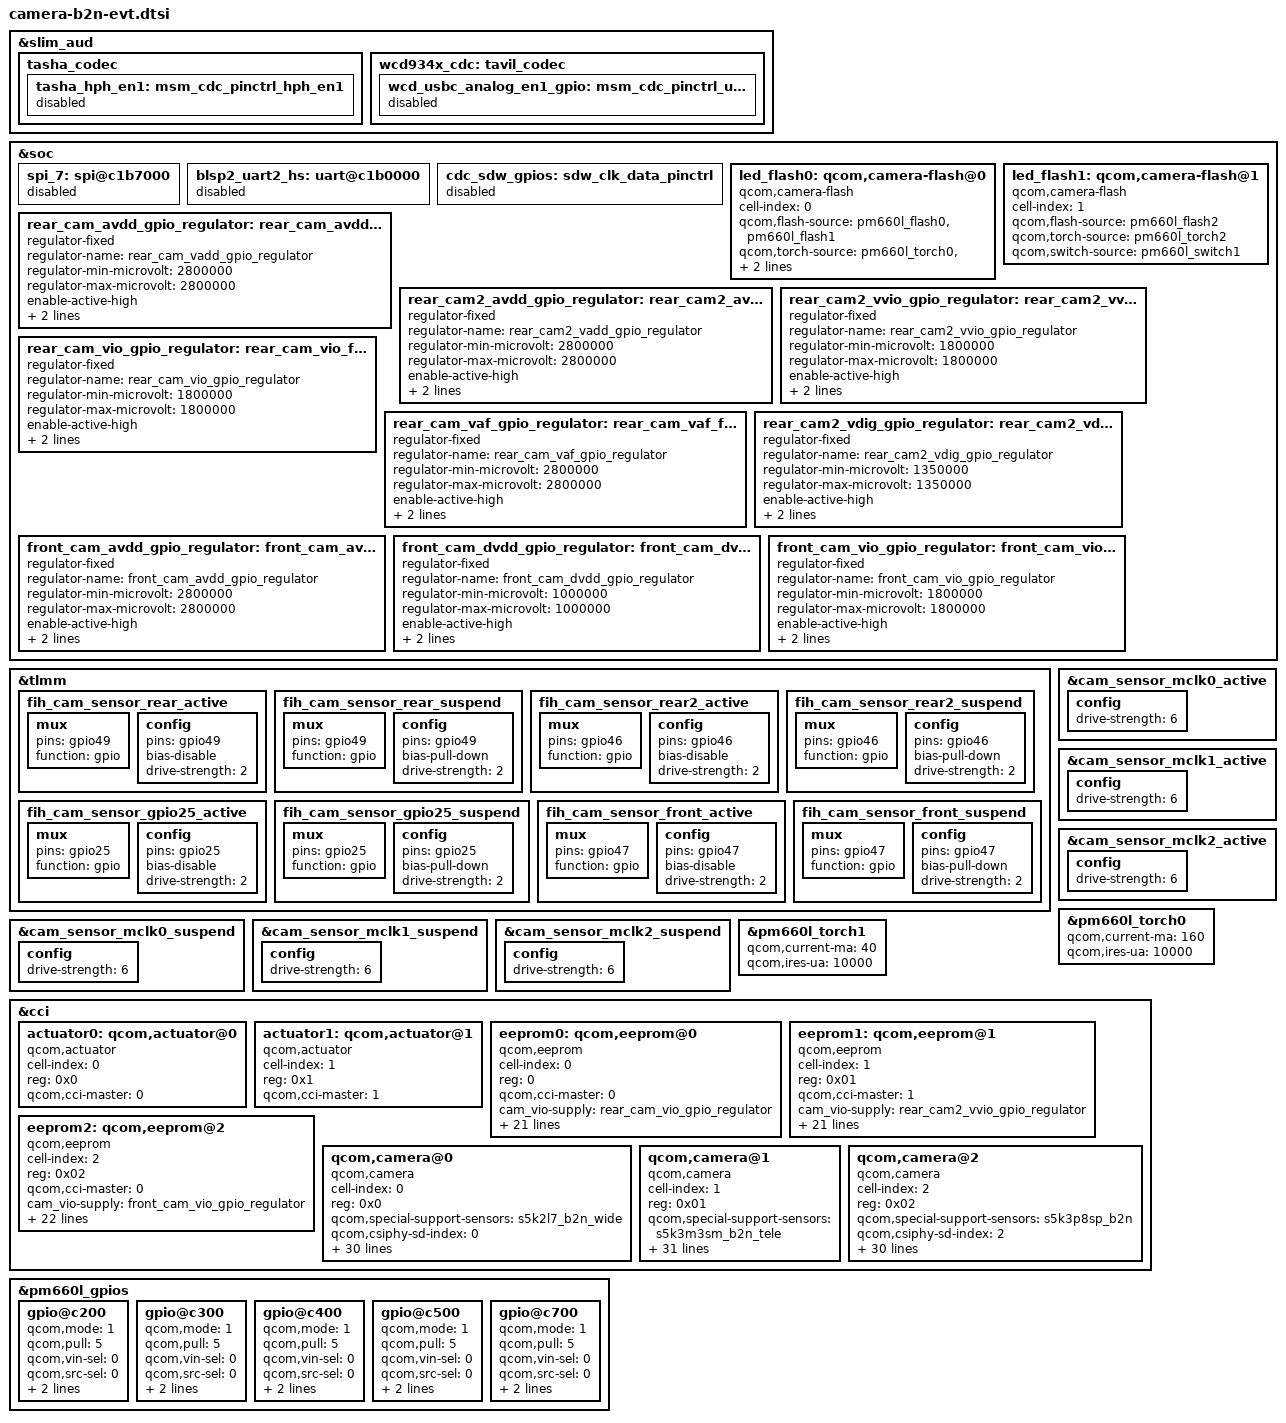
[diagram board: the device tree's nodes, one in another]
/*
 * Copyright (c) 2016, The Linux Foundation. All rights reserved.
 *
 * This program is free software; you can redistribute it and/or modify
 * it under the terms of the GNU General Public License version 2 and
 * only version 2 as published by the Free Software Foundation.
 *
 * This program is distributed in the hope that it will be useful,
 * but WITHOUT ANY WARRANTY; without even the implied warranty of
 * MERCHANTABILITY or FITNESS FOR A PARTICULAR PURPOSE.  See the
 * GNU General Public License for more details.
 */

&slim_aud {
	tasha_codec {
		tasha_hph_en1: msm_cdc_pinctrl_hph_en1 {
			status = "disabled";
		};
	};
	wcd934x_cdc: tavil_codec {
		wcd_usbc_analog_en1_gpio: msm_cdc_pinctrl_usbc_audio_en1 {
			status = "disabled";
		};
	};
};


&soc {
	spi_7: spi@c1b7000 { /* BLSP2 QUP3 */
		status = "disabled";
	};
	blsp2_uart2_hs: uart@c1b0000 { /* BLSP2 UART2 */
		status = "disabled";
	};
	cdc_sdw_gpios: sdw_clk_data_pinctrl {
	      status = "disabled";
	};

	led_flash0: qcom,camera-flash@0 {
		cell-index = <0>;
		compatible = "qcom,camera-flash";
		qcom,flash-source = <&pm660l_flash0 &pm660l_flash1>;
		qcom,torch-source = <&pm660l_torch0 &pm660l_torch1>;
		qcom,switch-source = <&pm660l_switch0>;
		status = "ok";
	};

	led_flash1: qcom,camera-flash@1 {
		cell-index = <1>;
		compatible = "qcom,camera-flash";
		qcom,flash-source = <&pm660l_flash2>;
		qcom,torch-source = <&pm660l_torch2>;
		qcom,switch-source = <&pm660l_switch1>;
		status = "ok";
	};

	/include/ "fih/nokia/camera/dummy_flash.dtsi"

	rear_cam_avdd_gpio_regulator: rear_cam_avdd_fixed_regulator {
		compatible = "regulator-fixed";
		regulator-name = "rear_cam_vadd_gpio_regulator";
		regulator-min-microvolt = <2800000>;
		regulator-max-microvolt = <2800000>;
		enable-active-high;
		gpio = <&tlmm 55 0>;
		vin-supply = <&pm660l_bob>;
	};

	rear_cam2_avdd_gpio_regulator: rear_cam2_avdd_fixed_regulator {
		compatible = "regulator-fixed";
		regulator-name = "rear_cam2_vadd_gpio_regulator";
		regulator-min-microvolt = <2800000>;
		regulator-max-microvolt = <2800000>;
		enable-active-high;
		gpio = <&tlmm 51 0>;
		vin-supply = <&pm660l_bob>;
	};

	rear_cam2_vvio_gpio_regulator: rear_cam2_vvio_fixed_regulator {
		compatible = "regulator-fixed";
		regulator-name = "rear_cam2_vvio_gpio_regulator";
		regulator-min-microvolt = <1800000>;
		regulator-max-microvolt = <1800000>;
		enable-active-high;
		gpio = <&tlmm 25 0>;
		vin-supply = <&pm660l_bob>;
	};

	rear_cam_vio_gpio_regulator: rear_cam_vio_fixed_regulator {
		compatible = "regulator-fixed";
		regulator-name = "rear_cam_vio_gpio_regulator";
		regulator-min-microvolt = <1800000>;
		regulator-max-microvolt = <1800000>;
		enable-active-high;
		gpio = <&pm660l_gpios 8 0>;
		vin-supply = <&pm660l_bob>;
	};

	rear_cam_vaf_gpio_regulator: rear_cam_vaf_fixed_regulator {
		compatible = "regulator-fixed";
		regulator-name = "rear_cam_vaf_gpio_regulator";
		regulator-min-microvolt = <2800000>;
		regulator-max-microvolt = <2800000>;
		enable-active-high;
		gpio = <&pm660l_gpios 6 0>;
		vin-supply = <&pm660l_bob>;
	};

	rear_cam2_vdig_gpio_regulator: rear_cam2_vdig_fixed_regulator {
		compatible = "regulator-fixed";
		regulator-name = "rear_cam2_vdig_gpio_regulator";
		regulator-min-microvolt = <1350000>;
		regulator-max-microvolt = <1350000>;
		enable-active-high;
		gpio = <&pm660l_gpios 4 0>;
		vin-supply = <&pm660l_bob>;
	};
	
	front_cam_avdd_gpio_regulator: front_cam_avdd_fixed_regulator {
		compatible = "regulator-fixed";
		regulator-name = "front_cam_avdd_gpio_regulator";
		regulator-min-microvolt = <2800000>;
		regulator-max-microvolt = <2800000>;
		enable-active-high;
		gpio = <&pm660l_gpios 5 0>;
		vin-supply = <&pm660l_bob>;
	};

	front_cam_dvdd_gpio_regulator: front_cam_dvdd_fixed_regulator {
		compatible = "regulator-fixed";
		regulator-name = "front_cam_dvdd_gpio_regulator";
		regulator-min-microvolt = <1000000>;
		regulator-max-microvolt = <1000000>;
		enable-active-high;
		gpio = <&pm660l_gpios 3 0>;
		vin-supply = <&pm660_s5>;
	};
	
	front_cam_vio_gpio_regulator: front_cam_vio_fixed_regulator {
		compatible = "regulator-fixed";
		regulator-name = "front_cam_vio_gpio_regulator";
		regulator-min-microvolt = <1800000>;
		regulator-max-microvolt = <1800000>;
		enable-active-high;
		gpio = <&pm660l_gpios 8 0>;
		vin-supply = <&pm660l_bob>;
	};
};

&tlmm {
		fih_cam_sensor_rear_active: fih_cam_sensor_rear_active {
			/* RESET */
			mux {
				pins = "gpio49";
				function = "gpio";
			};

			config {
				pins = "gpio49";
				bias-disable; /* No PULL */
				drive-strength = <2>; /* 2 MA */
			};
		};

		fih_cam_sensor_rear_suspend: fih_cam_sensor_rear_suspend {
			/* RESET */
			mux {
				pins = "gpio49";
				function = "gpio";
			};

			config {
				pins = "gpio49";
				bias-pull-down; /* PULL DOWN */
				drive-strength = <2>; /* 2 MA */
			};
		};
		fih_cam_sensor_rear2_active: fih_cam_sensor_rear2_active {
				/* RESET */
				mux {
					pins = "gpio46";
					function = "gpio";
				};

				config {
					pins = "gpio46";
					bias-disable; /* No PULL */
					drive-strength = <2>; /* 2 MA */
				};
			};

		fih_cam_sensor_rear2_suspend: fih_cam_sensor_rear2_suspend {
			/* RESET */
			mux {
				pins = "gpio46";
				function = "gpio";
			};

			config {
				pins = "gpio46";
				bias-pull-down; /* PULL DOWN */
				drive-strength = <2>; /* 2 MA */
			};
		};
		
		fih_cam_sensor_gpio25_active: fih_cam_sensor_gpio25_active {
				/* GPIO PWR */
				mux {
					pins = "gpio25";
					function = "gpio";
				};

				config {
					pins = "gpio25";
					bias-disable; /* No PULL */
					drive-strength = <2>; /* 2 MA */
				};
			};

		fih_cam_sensor_gpio25_suspend: fih_cam_sensor_gpio25_suspend {
			/* GPIO PWR */
			mux {
				pins = "gpio25";
				function = "gpio";
			};

			config {
				pins = "gpio25";
				bias-pull-down; /* PULL DOWN */
				drive-strength = <2>; /* 2 MA */
			};
		};

		fih_cam_sensor_front_active: fih_cam_sensor_front_active {
			/* RESET */
			mux {
				pins = "gpio47";
				function = "gpio";
			};

			config {
				pins = "gpio47";
				bias-disable; /* No PULL */
				drive-strength = <2>; /* 2 MA */
			};
		};

		fih_cam_sensor_front_suspend: fih_cam_sensor_front_suspend {
			/* RESET */
			mux {
				pins = "gpio47";
				function = "gpio";
			};

			config {
				pins = "gpio47";
				bias-pull-down; /* PULL DOWN */
				drive-strength = <2>; /* 2 MA */
			};
		};
};




/*Camera De-sense, raise mclk driving strength from 2MA to 6mA*/
&cam_sensor_mclk0_active {
			config {
				drive-strength = <6>; /* 6 MA */
			};
};
&cam_sensor_mclk0_suspend {
			config {
				drive-strength = <6>; /* 6 MA */
			};
};
&cam_sensor_mclk1_active {
			config {
				drive-strength = <6>; /* 6 MA */
			};
};
&cam_sensor_mclk1_suspend {
			config {
				drive-strength = <6>; /* 6 MA */
			};
};			
&cam_sensor_mclk2_active {
			config {
				drive-strength = <6>; /* 6 MA */
			};
};
&cam_sensor_mclk2_suspend {
			config {
				drive-strength = <6>; /* 6 MA */
			};
};

/*Modify Torch current*/
/*white*/
&pm660l_torch0 {
	qcom,current-ma = <160>;
	qcom,ires-ua = <10000>;
};

/*amber*/
&pm660l_torch1 {
	qcom,current-ma = <40>;
	qcom,ires-ua = <10000>;
};

/* CCI portion*/
&cci {
        /delete-node/qcom,camera@0;
        /delete-node/qcom,camera@1;
        /delete-node/qcom,camera@2;
		/delete-node/qcom,camera@3;
        /delete-node/qcom,eeprom@0;
        /delete-node/qcom,eeprom@1;
		/delete-node/qcom,eeprom@2;
        /delete-node/qcom,actuator@0;
        /delete-node/qcom,actuator@1;
		/delete-node/qcom,actuator@2;
        /delete-node/qcom,ois@0;
};

&cci {
	actuator0: qcom,actuator@0 {
		cell-index = <0>;
		reg = <0x0>;
		compatible = "qcom,actuator";
		qcom,cci-master = <0>;
	};

	actuator1: qcom,actuator@1 {
		cell-index = <1>;
		reg = <0x1>;
		compatible = "qcom,actuator";
		qcom,cci-master = <1>;
	};

	eeprom0: qcom,eeprom@0 {
		cell-index = <0>;
		reg = <0>;
		compatible = "qcom,eeprom";
		qcom,cci-master = <0>;
		cam_vio-supply = <&rear_cam_vio_gpio_regulator>;
		cam_vaf-supply = <&rear_cam_vaf_gpio_regulator>;
		qcom,cam-vreg-name = "cam_vio", "cam_vaf";
		qcom,cam-vreg-min-voltage = <1780000 0>;
		qcom,cam-vreg-max-voltage = <1950000 0>;
		qcom,cam-vreg-op-mode = <105000 80000>;
		qcom,gpio-no-mux = <0>;
		pinctrl-names = "cam_default", "cam_suspend";
		pinctrl-0 = <&cam_sensor_mclk2_active
				 &fih_cam_sensor_rear_active>;
		pinctrl-1 = <&cam_sensor_mclk2_suspend
				 &fih_cam_sensor_rear_suspend>;
		gpios = <&tlmm 34 0>,
			<&tlmm 49 0>,
			<&tlmm 55 0>,
			<&tlmm 56 0>;
		qcom,gpio-reset = <1>;
		qcom,gpio-vana = <2>;
		qcom,gpio-vdig = <3>;
		qcom,gpio-req-tbl-num = <0 1 2 3>;
		qcom,gpio-req-tbl-flags = <1 0 0 0>;
		qcom,gpio-req-tbl-label = "CAMIF_MCLK",
					"CAM_RESET",
					"CAM_VANA",
					"CAM_VDIG";
		clocks = <&clock_mmss MCLK2_CLK_SRC>,
			<&clock_mmss MMSS_CAMSS_MCLK2_CLK>;
		clock-names = "cam_src_clk", "cam_clk";
		qcom,clock-rates = <24000000 0>;
	};

	eeprom1: qcom,eeprom@1 {
		cell-index = <1>;
		reg = <0x01>;
		compatible = "qcom,eeprom";
		qcom,cci-master = <1>;		
		cam_vio-supply = <&rear_cam2_vvio_gpio_regulator>;
		cam_vdig-supply = <&rear_cam2_vdig_gpio_regulator>;
		qcom,cam-vreg-name = "cam_vio","cam_vdig";
		qcom,cam-vreg-min-voltage = <1780000 0>;
		qcom,cam-vreg-max-voltage = <1950000 0>;
		qcom,cam-vreg-op-mode = <105000 80000>;
		qcom,gpio-no-mux = <0>;
		pinctrl-names = "cam_default", "cam_suspend";
		pinctrl-0 = <&cam_sensor_mclk0_active
				 &fih_cam_sensor_rear2_active>;
				 /*&fih_cam_sensor_gpio25_active>;*/
		pinctrl-1 = <&cam_sensor_mclk0_suspend
				 &fih_cam_sensor_rear2_suspend>;
				 /*&fih_cam_sensor_gpio25_suspend>;*/
		gpios = <&tlmm 32 0>,
			<&tlmm 46 0>,
			/*<&tlmm 25 0>,*/
			<&tlmm 50 0>,
			<&tlmm 51 0>;
		qcom,gpio-reset = <1>;
		/*qcom,gpio-vio = <2>;*/
		qcom,gpio-vaf = <2>;//3
		qcom,gpio-vana = <3>;//4
		qcom,gpio-req-tbl-num = <0 1 2 3>;//01234
		qcom,gpio-req-tbl-flags = <1 0 0 0>;//10000
		qcom,gpio-req-tbl-label = "CAMIF_MCLK0",
					"CAM_RESET0",
					/*"CAM_VIO",*/
					"CAM_VAF",
					"CAM_VANA";
		clocks = <&clock_mmss MCLK0_CLK_SRC>,
			<&clock_mmss MMSS_CAMSS_MCLK0_CLK>;
		clock-names = "cam_src_clk", "cam_clk";
		qcom,clock-rates = <24000000 0>;
	};

    eeprom2: qcom,eeprom@2 {
		cell-index = <2>;
		reg = <0x02>;
		compatible = "qcom,eeprom";
		qcom,cci-master = <0>;
		cam_vio-supply = <&front_cam_vio_gpio_regulator>;
		cam_vana-supply = <&front_cam_avdd_gpio_regulator>;
		cam_vdig-supply = <&front_cam_dvdd_gpio_regulator>;
		qcom,cam-vreg-name = "cam_vio", "cam_vana", "cam_vdig";
		qcom,cam-vreg-min-voltage = <1780000 0 0>;
		qcom,cam-vreg-max-voltage = <1950000 0 0>;
		qcom,cam-vreg-op-mode = <105000 80000 105000>;
		qcom,gpio-no-mux = <0>;
		pinctrl-names = "cam_default", "cam_suspend";
		pinctrl-0 = <&cam_sensor_mclk1_active
				&fih_cam_sensor_front_active>;
		pinctrl-1 = <&cam_sensor_mclk1_suspend
				&fih_cam_sensor_front_suspend>;
		gpios = <&tlmm 33 0>,
			<&tlmm 47 0>,
			<&tlmm 40 0>;
		qcom,gpio-reset = <1>;
		qcom,gpio-custom1 = <2>;
		qcom,gpio-req-tbl-num = <0 1 2>;
		qcom,gpio-req-tbl-flags = <1 0 0>;
		qcom,gpio-req-tbl-label = "FRONT_MCLK",
					"FRONT_RESET",
					"FRONT_CUSTOM1";
		clocks = <&clock_mmss MCLK1_CLK_SRC>,
				<&clock_mmss MMSS_CAMSS_MCLK1_CLK>;
		clock-names = "cam_src_clk", "cam_clk";
		qcom,clock-rates = <24000000 0>;
	};

	qcom,camera@0 { //wide
		cell-index = <0>;
		compatible = "qcom,camera";
		reg = <0x0>;
		qcom,special-support-sensors = "s5k2l7_b2n_wide";
		qcom,csiphy-sd-index = <0>;
		qcom,csid-sd-index = <0>;
		qcom,mount-angle = <270>;
		qcom,led-flash-src = <&led_flash0>;
		qcom,actuator-src = <&actuator0>;
		qcom,eeprom-src = <&eeprom0>;
		/*cam_vio-supply = <&pm660_l11>;*/
		cam_vio-supply = <&rear_cam_vio_gpio_regulator>;
		/*cam_vana-supply = <&rear_cam_avdd_gpio_regulator>;*/
		/*cam_vdig-supply = <&rear_cam_dvdd_gpio_regulator>;*/
		cam_vaf-supply = <&rear_cam_vaf_gpio_regulator>;
		qcom,cam-vreg-name = "cam_vio", "cam_vaf";
		qcom,cam-vreg-min-voltage = <1780000 0>;
		qcom,cam-vreg-max-voltage = <1950000 0>;
		qcom,cam-vreg-op-mode = <105000 80000>;
		qcom,gpio-no-mux = <0>;
		pinctrl-names = "cam_default", "cam_suspend";
		pinctrl-0 = <&cam_sensor_mclk2_active
				 &fih_cam_sensor_rear_active>;
		pinctrl-1 = <&cam_sensor_mclk2_suspend
				 &fih_cam_sensor_rear_suspend>;
		gpios = <&tlmm 34 0>,
			<&tlmm 49 0>,
			<&tlmm 55 0>,
			<&tlmm 56 0>;
		qcom,gpio-reset = <1>;
		qcom,gpio-vana = <2>;
		qcom,gpio-vdig = <3>;
		/*qcom,gpio-custom1 = <2>;*/
		/*qcom,gpio-custom2 = <3>;*/
		qcom,gpio-req-tbl-num = <0 1 2 3>;
		qcom,gpio-req-tbl-flags = <1 0 0 0>;
		qcom,gpio-req-tbl-label = "CAMIF_MCLK",
					"CAM_RESET",
					"CAM_VANA",
					"CAM_VDIG";
		qcom,sensor-position = <0>;
		qcom,sensor-mode = <0>;
		qcom,cci-master = <0>;
		status = "ok";
		clocks = <&clock_mmss MCLK2_CLK_SRC>,
			<&clock_mmss MMSS_CAMSS_MCLK2_CLK>;
		clock-names = "cam_src_clk", "cam_clk";
		qcom,clock-rates = <24000000 0>;
	};

	qcom,camera@1 { //tele
		cell-index = <1>;
		compatible = "qcom,camera";
		reg = <0x01>;
		qcom,special-support-sensors = "s5k3m3sm_b2n_tele";
		qcom,eeprom-src = <&eeprom1>;
		qcom,csiphy-sd-index = <1>;
		qcom,csid-sd-index = <1>;
		qcom,mount-angle = <90>;
		qcom,led-flash-src = <&led_flash0>;/* MM-MC-AddForS5k3m3smTele-00+ */
		qcom,actuator-src = <&actuator1>;
		qcom,eeprom-src = <&eeprom1>;
		cam_vio-supply = <&rear_cam2_vvio_gpio_regulator>;
		/*cam_vio-supply = <&pm660_l11>;*/
		/*cam_vana-supply = <&front_cam_avdd_gpio_regulator>;*/
		/*cam_vdig-supply = <&pm660_s4>;*/
		cam_vdig-supply = <&rear_cam2_vdig_gpio_regulator>;
		qcom,cam-vreg-name = "cam_vio","cam_vdig";
		qcom,cam-vreg-min-voltage = <1780000 0>;
		qcom,cam-vreg-max-voltage = <1950000 0>;
		qcom,cam-vreg-op-mode = <105000 80000>;
		qcom,gpio-no-mux = <0>;
		pinctrl-names = "cam_default", "cam_suspend";
		pinctrl-0 = <&cam_sensor_mclk0_active
				 &fih_cam_sensor_rear2_active>;
				 /*&fih_cam_sensor_gpio25_active>;*/
		pinctrl-1 = <&cam_sensor_mclk0_suspend
				 &fih_cam_sensor_rear2_suspend>;
				 /*&fih_cam_sensor_gpio25_suspend>;*/
		gpios = <&tlmm 32 0>,
			<&tlmm 46 0>,
			/*<&tlmm 25 0>,*/
			<&tlmm 50 0>,
			<&tlmm 51 0>;
		qcom,gpio-reset = <1>;
		/*qcom,gpio-vio = <2>;*/
		qcom,gpio-vaf = <2>;//3
		qcom,gpio-vana = <3>;//4
		qcom,gpio-req-tbl-num = <0 1 2 3>;//01234
		qcom,gpio-req-tbl-flags = <1 0 0 0>;//10000
		qcom,gpio-req-tbl-label = "CAMIF_MCLK0",
					"CAM_RESET0",
					/*"CAM_VIO",*/
					"CAM_VAF",
					"CAM_VANA";
		qcom,sensor-position = <0>;
		qcom,sensor-mode = <0>;
		qcom,cci-master = <1>;
		status = "ok";
		clocks = <&clock_mmss MCLK0_CLK_SRC>,
			<&clock_mmss MMSS_CAMSS_MCLK0_CLK>;
		clock-names = "cam_src_clk", "cam_clk";
		qcom,clock-rates = <24000000 0>;
	};	

/*	
	qcom,camera@0 { //wide
		cell-index = <0>;
		compatible = "qcom,camera";
		reg = <0x0>;
		qcom,special-support-sensors = "s5k2l7sa_s3p";
		qcom,csiphy-sd-index = <0>;
		qcom,csid-sd-index = <0>;
		qcom,mount-angle = <90>;
		qcom,led-flash-src = <&led_flash0>;
		qcom,actuator-src = <&actuator0>;
		qcom,eeprom-src = <&eeprom0>;
		cam_vio-supply = <&pm660_l11>;
		cam_vana-supply = <&rear_cam_avdd_gpio_regulator>;
		cam_vdig-supply = <&pm660_s5>;
		cam_vaf-supply = <&rear_cam_vaf_gpio_regulator>;
		qcom,cam-vreg-name = "cam_vio", "cam_vana", "cam_vdig", "cam_vaf";
		qcom,cam-vreg-min-voltage = <1780000 0 0 0>;
		qcom,cam-vreg-max-voltage = <1950000 0 0 0>;
		qcom,cam-vreg-op-mode = <105000 80000 105000 80000>;
		qcom,gpio-no-mux = <0>;
		pinctrl-names = "cam_default", "cam_suspend";
		pinctrl-0 = <&cam_sensor_mclk2_active
				 &fih_cam_sensor_rear_active>;
		pinctrl-1 = <&cam_sensor_mclk2_suspend
				 &fih_cam_sensor_rear_suspend>;
		gpios = <&tlmm 34 0>,
			<&tlmm 49 0>,
			<&tlmm 56 0>;
		qcom,gpio-reset = <1>;
		qcom,gpio-vdig = <2>;
		qcom,gpio-req-tbl-num = <0 1 2>;
		qcom,gpio-req-tbl-flags = <1 0 0>;
		qcom,gpio-req-tbl-label = "CAMIF_MCLK",
					"CAM_RESET",
					"CAM_VDIG_CA0";
		qcom,sensor-position = <0>;
		qcom,sensor-mode = <0>;
		qcom,cci-master = <0>;
		status = "ok";
		clocks = <&clock_mmss MCLK2_CLK_SRC>,
				<&clock_mmss MMSS_CAMSS_MCLK2_CLK>;
		clock-names = "cam_src_clk", "cam_clk";
		qcom,clock-rates = <24000000 0>;
	};

	qcom,camera@1 {//tele
		cell-index = <1>;
		compatible = "qcom,camera";
		reg = <0x1>;
		qcom,special-support-sensors = "s5k3m3sm_s3p";
		qcom,csiphy-sd-index = <1>;
		qcom,csid-sd-index = <1>;
		qcom,mount-angle = <90>;
		qcom,actuator-src = <&actuator1>;
		qcom,eeprom-src = <&eeprom1>;
		cam_vio-supply = <&pm660_l11>;
		cam_vana-supply = <&rear_cam_avdd_gpio_regulator>;
		cam_vdig-supply = <&pm660_s5>;
		qcom,cam-vreg-name = "cam_vio", "cam_vana", "cam_vdig";
		qcom,cam-vreg-min-voltage = <1780000 0 0>;
		qcom,cam-vreg-max-voltage = <1950000 0 0>;
		qcom,cam-vreg-op-mode = <105000 80000 105000>;
		qcom,gpio-no-mux = <0>;
		pinctrl-names = "cam_default", "cam_suspend";
		pinctrl-0 = <&cam_sensor_mclk0_active
				 &fih_cam_sensor_rear2_active>;
		pinctrl-1 = <&cam_sensor_mclk0_suspend
				 &fih_cam_sensor_rear2_suspend>;
		gpios = <&tlmm 32 0>,
			<&tlmm 46 0>,
			<&pm660l_gpios 4 0>;
		qcom,gpio-reset = <1>;
		qcom,gpio-vdig = <2>;
		qcom,gpio-req-tbl-num = <0 1 2>;
		qcom,gpio-req-tbl-flags = <1 0 0>;
		qcom,gpio-req-tbl-label = "CAMIF_MCLK",
					"CAM_RESET",
					"CAM_VDIG_CA1";
		qcom,sensor-position = <0>;
		qcom,sensor-mode = <0>;
		qcom,cci-master = <1>;
		status = "ok";
		clocks = <&clock_mmss MCLK0_CLK_SRC>,
			<&clock_mmss MMSS_CAMSS_MCLK0_CLK>;
		clock-names = "cam_src_clk", "cam_clk";
		qcom,clock-rates = <24000000 0>;
	};
*/

	qcom,camera@2 {//front
		cell-index = <2>;
		compatible = "qcom,camera";
		reg = <0x02>;
		qcom,special-support-sensors = "s5k3p8sp_b2n";
		qcom,csiphy-sd-index = <2>;
		qcom,csid-sd-index = <2>;
		qcom,mount-angle = <90>;
		qcom,led-flash-src = <&led_flash2>;
		qcom,eeprom-src = <&eeprom2>;
		cam_vio-supply = <&front_cam_vio_gpio_regulator>;
		cam_vana-supply = <&front_cam_avdd_gpio_regulator>;
		cam_vdig-supply = <&front_cam_dvdd_gpio_regulator>;
		qcom,cam-vreg-name = "cam_vio", "cam_vana", "cam_vdig";
		qcom,cam-vreg-min-voltage = <1780000 0 0>;
		qcom,cam-vreg-max-voltage = <1950000 0 0>;
		qcom,cam-vreg-op-mode = <105000 80000 105000>;
		qcom,gpio-no-mux = <0>;
		pinctrl-names = "cam_default", "cam_suspend";
		pinctrl-0 = <&cam_sensor_mclk1_active
				 &fih_cam_sensor_front_active>;
		pinctrl-1 = <&cam_sensor_mclk1_suspend
				 &fih_cam_sensor_front_suspend>;
		gpios = <&tlmm 33 0>,
			<&tlmm 47 0>,
			<&tlmm 40 0>;
		qcom,gpio-reset = <1>;
		qcom,gpio-custom1 = <2>;
		qcom,gpio-req-tbl-num = <0 1 2>;
		qcom,gpio-req-tbl-flags = <1 0 0>;
		qcom,gpio-req-tbl-label = "FRONT_MCLK",
					"FRONT_RESET",
					"FRONT_CUSTOM1";
		qcom,sensor-position = <1>;
		qcom,sensor-mode = <0>;
		qcom,cci-master = <0>;
		status = "ok";
		clocks = <&clock_mmss MCLK1_CLK_SRC>,
			<&clock_mmss MMSS_CAMSS_MCLK1_CLK>;
		clock-names = "cam_src_clk", "cam_clk";
		qcom,clock-rates = <24000000 0>;
	};
};

&pm660l_gpios {
	gpio@c200 { /* GPIO3 - VDIG */
		qcom,mode = <1>;                /* Output */
		qcom,pull = <5>;                /* No Pull */
		qcom,vin-sel = <0>;             /* VIN1 GPIO_LV */
		qcom,src-sel = <0>;             /* GPIO */
		qcom,invert = <0>;              /* Invert */
		qcom,master-en = <1>;           /* Enable GPIO */
		status = "ok";
	};
	
	gpio@c300 { /* GPIO4 */
		qcom,mode = <1>;                /* Output */
		qcom,pull = <5>;                /* No Pull */
		qcom,vin-sel = <0>;             /* VIN1 GPIO_LV */
		qcom,src-sel = <0>;             /* GPIO */
		qcom,invert = <0>;              /* Invert */
		qcom,master-en = <1>;           /* Enable GPIO */
		status = "ok";
	};
	
	gpio@c400 { /* GPIO5 - VANA */
		qcom,mode = <1>;                /* Output */
		qcom,pull = <5>;                /* No Pull */
		qcom,vin-sel = <0>;             /* VIN1 GPIO_LV */
		qcom,src-sel = <0>;             /* GPIO */
		qcom,invert = <0>;              /* Invert */
		qcom,master-en = <1>;           /* Enable GPIO */
		status = "ok";
	};
	
	gpio@c500 { /* GPIO6 */
		qcom,mode = <1>;                /* Output */
		qcom,pull = <5>;                /* No Pull */
		qcom,vin-sel = <0>;             /* VIN1 GPIO_LV */
		qcom,src-sel = <0>;             /* GPIO */
		qcom,invert = <0>;              /* Invert */
		qcom,master-en = <1>;           /* Enable GPIO */
		status = "ok";
	};
	
	gpio@c700 { /* GPIO8 */
		qcom,mode = <1>;                /* Output */
		qcom,pull = <5>;                /* No Pull */
		qcom,vin-sel = <0>;             /* VIN1 GPIO_LV */
		qcom,src-sel = <0>;             /* GPIO */
		qcom,invert = <0>;              /* Invert */
		qcom,master-en = <1>;           /* Enable GPIO */
		status = "ok";
	};
};
